VERSION ""

NS_ :

BS_:

BU_:

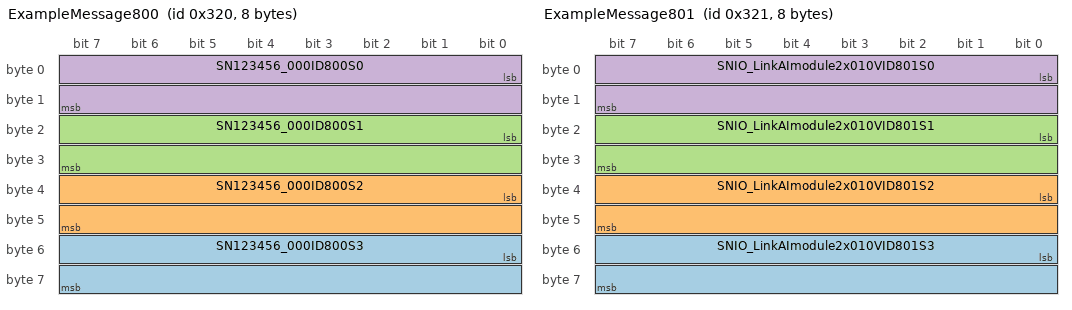
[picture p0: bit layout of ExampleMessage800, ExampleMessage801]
BO_ 800 ExampleMessage800: 8 Vector__XXX
 SG_ SN123456_000ID800S3 : 48|16@1+ (1,0) [-3000|3000] "unit" Vector__XXX
 SG_ SN123456_000ID800S2 : 32|16@1+ (1,0) [-3000|3000] "unit" Vector__XXX
 SG_ SN123456_000ID800S1 : 16|16@1+ (1,0) [-3000|3000] "unit" Vector__XXX
 SG_ SN123456_000ID800S0 : 0|16@1+ (1,0) [-3000|3000] "unit" Vector__XXX

BO_ 801 ExampleMessage801: 8 Vector__XXX
 SG_ SNIO_LinkAImodule2x010VID801S3 : 48|16@1+ (1,0) [-3000|3000] "unit" Vector__XXX
 SG_ SNIO_LinkAImodule2x010VID801S2 : 32|16@1+ (1,0) [-3000|3000] "unit" Vector__XXX
 SG_ SNIO_LinkAImodule2x010VID801S1 : 16|16@1+ (1,0) [-3000|3000] "unit" Vector__XXX
 SG_ SNIO_LinkAImodule2x010VID801S0 : 0|16@1+ (1,0) [-3000|3000] "unit" Vector__XXX

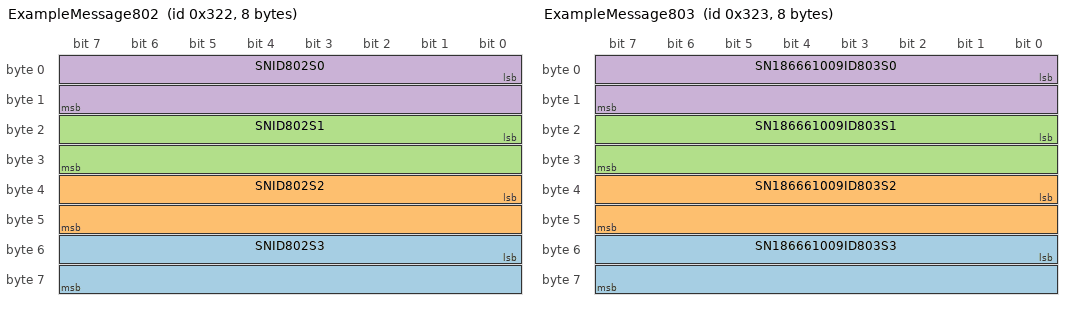
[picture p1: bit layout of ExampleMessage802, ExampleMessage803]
BO_ 802 ExampleMessage802: 8 Vector__XXX
 SG_ SNID802S3 : 48|16@1+ (1,0) [-3000|3000] "unit" Vector__XXX
 SG_ SNID802S2 : 32|16@1+ (1,0) [-3000|3000] "unit" Vector__XXX
 SG_ SNID802S1 : 16|16@1+ (1,0) [-3000|3000] "unit" Vector__XXX
 SG_ SNID802S0 : 0|16@1+ (1,0) [-3000|3000] "unit" Vector__XXX

BO_ 803 ExampleMessage803: 8 Vector__XXX
 SG_ SN186661009ID803S3 : 48|16@1+ (1,0) [-3000|3000] "unit" Vector__XXX
 SG_ SN186661009ID803S2 : 32|16@1+ (1,0) [-3000|3000] "unit" Vector__XXX
 SG_ SN186661009ID803S1 : 16|16@1+ (1,0) [-3000|3000] "unit" Vector__XXX
 SG_ SN186661009ID803S0 : 0|16@1+ (1,0) [-3000|3000] "unit" Vector__XXX

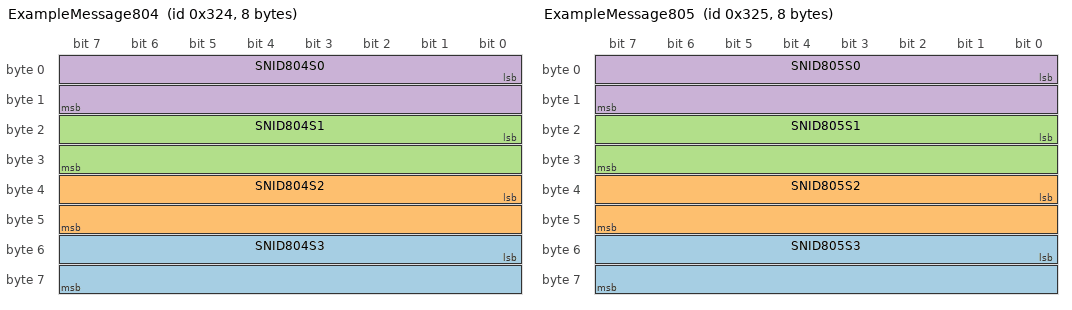
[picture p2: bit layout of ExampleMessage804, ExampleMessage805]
BO_ 804 ExampleMessage804: 8 Vector__XXX
 SG_ SNID804S3 : 48|16@1+ (1,0) [-3000|3000] "unit" Vector__XXX
 SG_ SNID804S2 : 32|16@1+ (1,0) [-3000|3000] "unit" Vector__XXX
 SG_ SNID804S1 : 16|16@1+ (1,0) [-3000|3000] "unit" Vector__XXX
 SG_ SNID804S0 : 0|16@1+ (1,0) [-3000|3000] "unit" Vector__XXX

BO_ 805 ExampleMessage805: 8 Vector__XXX
 SG_ SNID805S3 : 48|16@1+ (1,0) [-3000|3000] "unit" Vector__XXX
 SG_ SNID805S2 : 32|16@1+ (1,0) [-3000|3000] "unit" Vector__XXX
 SG_ SNID805S1 : 16|16@1+ (1,0) [-3000|3000] "unit" Vector__XXX
 SG_ SNID805S0 : 0|16@1+ (1,0) [-3000|3000] "unit" Vector__XXX

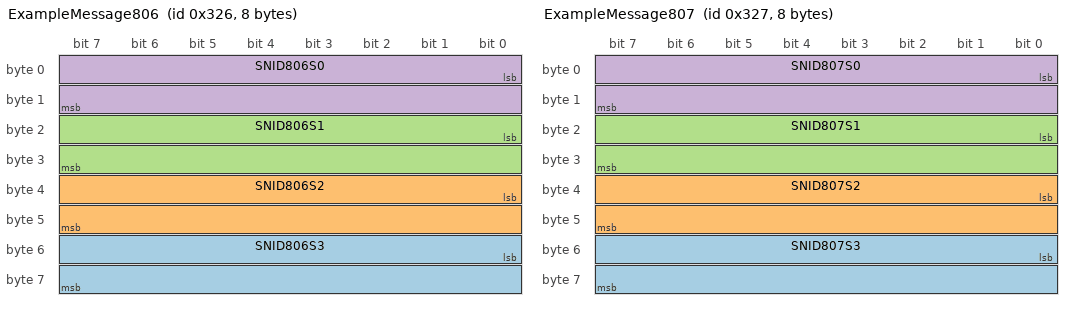
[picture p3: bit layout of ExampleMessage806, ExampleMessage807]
BO_ 806 ExampleMessage806: 8 Vector__XXX
 SG_ SNID806S3 : 48|16@1+ (1,0) [-3000|3000] "unit" Vector__XXX
 SG_ SNID806S2 : 32|16@1+ (1,0) [-3000|3000] "unit" Vector__XXX
 SG_ SNID806S1 : 16|16@1+ (1,0) [-3000|3000] "unit" Vector__XXX
 SG_ SNID806S0 : 0|16@1+ (1,0) [-3000|3000] "unit" Vector__XXX

BO_ 807 ExampleMessage807: 8 Vector__XXX
 SG_ SNID807S3 : 48|16@1+ (1,0) [-3000|3000] "unit" Vector__XXX
 SG_ SNID807S2 : 32|16@1+ (1,0) [-3000|3000] "unit" Vector__XXX
 SG_ SNID807S1 : 16|16@1+ (1,0) [-3000|3000] "unit" Vector__XXX
 SG_ SNID807S0 : 0|16@1+ (1,0) [-3000|3000] "unit" Vector__XXX

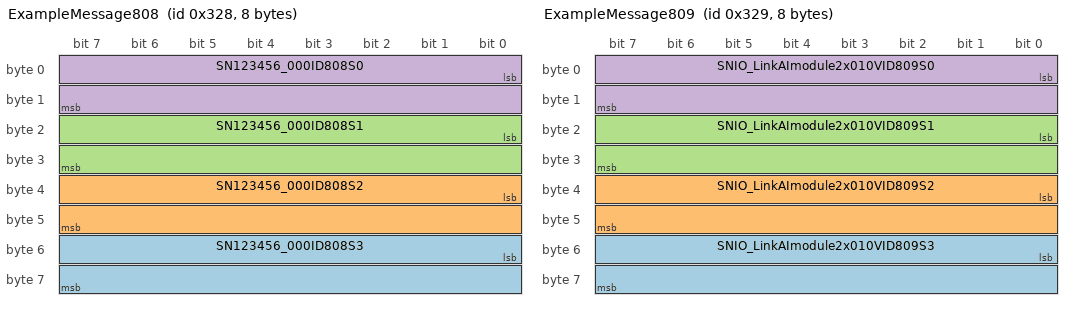
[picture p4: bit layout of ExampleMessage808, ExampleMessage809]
BO_ 808 ExampleMessage808: 8 Vector__XXX
 SG_ SN123456_000ID808S3 : 48|16@1+ (1,0) [-3000|3000] "unit" Vector__XXX
 SG_ SN123456_000ID808S2 : 32|16@1+ (1,0) [-3000|3000] "unit" Vector__XXX
 SG_ SN123456_000ID808S1 : 16|16@1+ (1,0) [-3000|3000] "unit" Vector__XXX
 SG_ SN123456_000ID808S0 : 0|16@1+ (1,0) [-3000|3000] "unit" Vector__XXX

BO_ 809 ExampleMessage809: 8 Vector__XXX
 SG_ SNIO_LinkAImodule2x010VID809S3 : 48|16@1+ (1,0) [-3000|3000] "unit" Vector__XXX
 SG_ SNIO_LinkAImodule2x010VID809S2 : 32|16@1+ (1,0) [-3000|3000] "unit" Vector__XXX
 SG_ SNIO_LinkAImodule2x010VID809S1 : 16|16@1+ (1,0) [-3000|3000] "unit" Vector__XXX
 SG_ SNIO_LinkAImodule2x010VID809S0 : 0|16@1+ (1,0) [-3000|3000] "unit" Vector__XXX

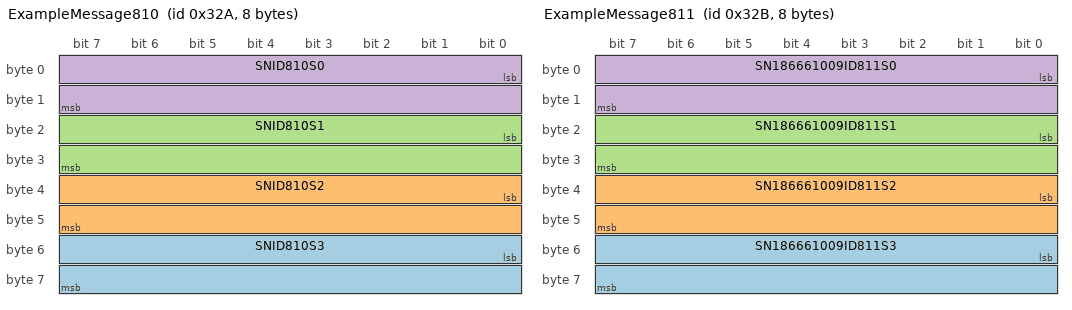
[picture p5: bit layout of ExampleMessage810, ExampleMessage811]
BO_ 810 ExampleMessage810: 8 Vector__XXX
 SG_ SNID810S3 : 48|16@1+ (1,0) [-3000|3000] "unit" Vector__XXX
 SG_ SNID810S2 : 32|16@1+ (1,0) [-3000|3000] "unit" Vector__XXX
 SG_ SNID810S1 : 16|16@1+ (1,0) [-3000|3000] "unit" Vector__XXX
 SG_ SNID810S0 : 0|16@1+ (1,0) [-3000|3000] "unit" Vector__XXX

BO_ 811 ExampleMessage811: 8 Vector__XXX
 SG_ SN186661009ID811S3 : 48|16@1+ (1,0) [-3000|3000] "unit" Vector__XXX
 SG_ SN186661009ID811S2 : 32|16@1+ (1,0) [-3000|3000] "unit" Vector__XXX
 SG_ SN186661009ID811S1 : 16|16@1+ (1,0) [-3000|3000] "unit" Vector__XXX
 SG_ SN186661009ID811S0 : 0|16@1+ (1,0) [-3000|3000] "unit" Vector__XXX

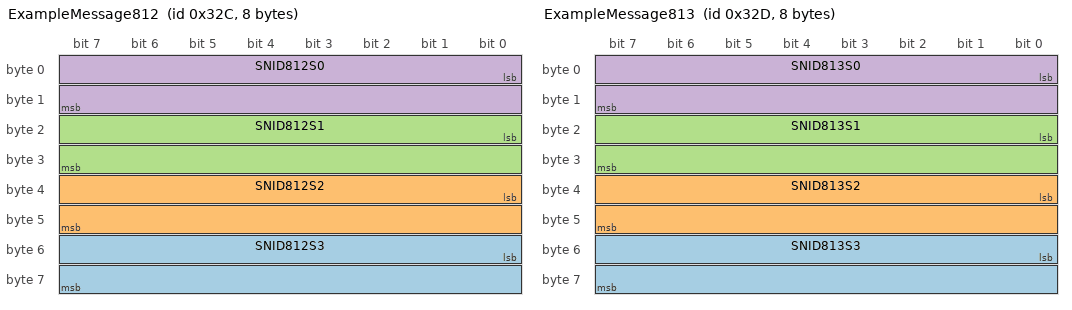
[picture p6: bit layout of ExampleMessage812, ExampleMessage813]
BO_ 812 ExampleMessage812: 8 Vector__XXX
 SG_ SNID812S3 : 48|16@1+ (1,0) [-3000|3000] "unit" Vector__XXX
 SG_ SNID812S2 : 32|16@1+ (1,0) [-3000|3000] "unit" Vector__XXX
 SG_ SNID812S1 : 16|16@1+ (1,0) [-3000|3000] "unit" Vector__XXX
 SG_ SNID812S0 : 0|16@1+ (1,0) [-3000|3000] "unit" Vector__XXX

BO_ 813 ExampleMessage813: 8 Vector__XXX
 SG_ SNID813S3 : 48|16@1+ (1,0) [-3000|3000] "unit" Vector__XXX
 SG_ SNID813S2 : 32|16@1+ (1,0) [-3000|3000] "unit" Vector__XXX
 SG_ SNID813S1 : 16|16@1+ (1,0) [-3000|3000] "unit" Vector__XXX
 SG_ SNID813S0 : 0|16@1+ (1,0) [-3000|3000] "unit" Vector__XXX

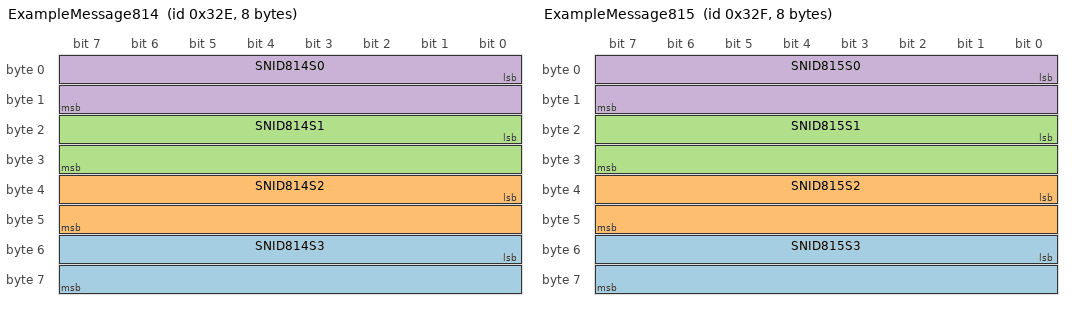
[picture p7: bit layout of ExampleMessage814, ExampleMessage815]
BO_ 814 ExampleMessage814: 8 Vector__XXX
 SG_ SNID814S3 : 48|16@1+ (1,0) [-3000|3000] "unit" Vector__XXX
 SG_ SNID814S2 : 32|16@1+ (1,0) [-3000|3000] "unit" Vector__XXX
 SG_ SNID814S1 : 16|16@1+ (1,0) [-3000|3000] "unit" Vector__XXX
 SG_ SNID814S0 : 0|16@1+ (1,0) [-3000|3000] "unit" Vector__XXX

BO_ 815 ExampleMessage815: 8 Vector__XXX
 SG_ SNID815S3 : 48|16@1+ (1,0) [-3000|3000] "unit" Vector__XXX
 SG_ SNID815S2 : 32|16@1+ (1,0) [-3000|3000] "unit" Vector__XXX
 SG_ SNID815S1 : 16|16@1+ (1,0) [-3000|3000] "unit" Vector__XXX
 SG_ SNID815S0 : 0|16@1+ (1,0) [-3000|3000] "unit" Vector__XXX

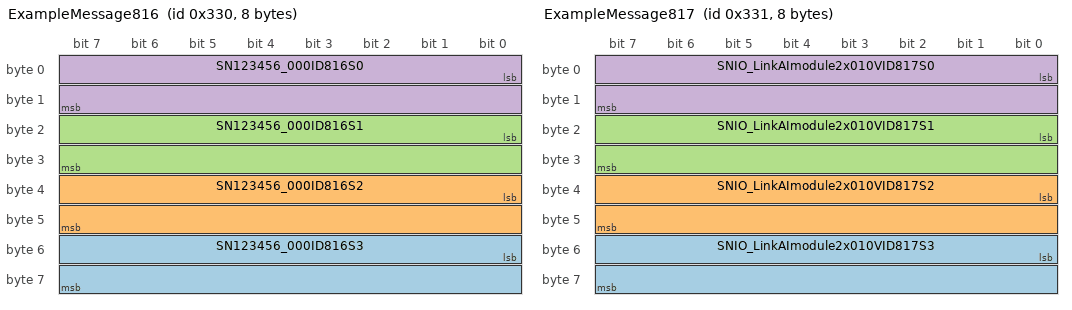
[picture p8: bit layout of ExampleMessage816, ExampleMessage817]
BO_ 816 ExampleMessage816: 8 Vector__XXX
 SG_ SN123456_000ID816S3 : 48|16@1+ (1,0) [-3000|3000] "unit" Vector__XXX
 SG_ SN123456_000ID816S2 : 32|16@1+ (1,0) [-3000|3000] "unit" Vector__XXX
 SG_ SN123456_000ID816S1 : 16|16@1+ (1,0) [-3000|3000] "unit" Vector__XXX
 SG_ SN123456_000ID816S0 : 0|16@1+ (1,0) [-3000|3000] "unit" Vector__XXX

BO_ 817 ExampleMessage817: 8 Vector__XXX
 SG_ SNIO_LinkAImodule2x010VID817S3 : 48|16@1+ (1,0) [-3000|3000] "unit" Vector__XXX
 SG_ SNIO_LinkAImodule2x010VID817S2 : 32|16@1+ (1,0) [-3000|3000] "unit" Vector__XXX
 SG_ SNIO_LinkAImodule2x010VID817S1 : 16|16@1+ (1,0) [-3000|3000] "unit" Vector__XXX
 SG_ SNIO_LinkAImodule2x010VID817S0 : 0|16@1+ (1,0) [-3000|3000] "unit" Vector__XXX

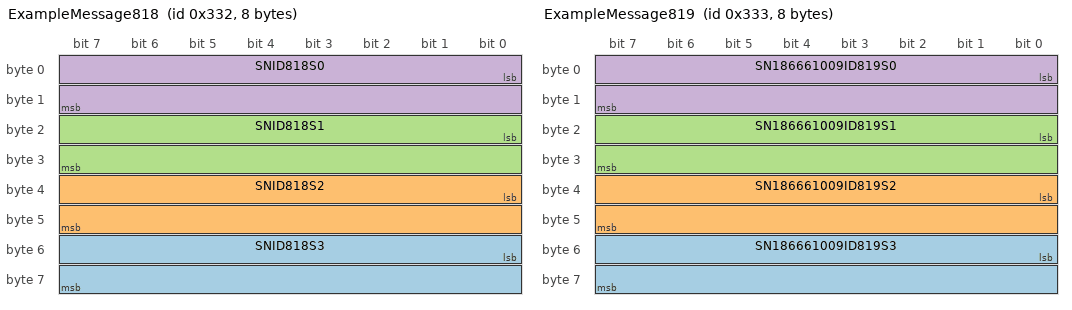
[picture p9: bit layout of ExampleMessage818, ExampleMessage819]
BO_ 818 ExampleMessage818: 8 Vector__XXX
 SG_ SNID818S3 : 48|16@1+ (1,0) [-3000|3000] "unit" Vector__XXX
 SG_ SNID818S2 : 32|16@1+ (1,0) [-3000|3000] "unit" Vector__XXX
 SG_ SNID818S1 : 16|16@1+ (1,0) [-3000|3000] "unit" Vector__XXX
 SG_ SNID818S0 : 0|16@1+ (1,0) [-3000|3000] "unit" Vector__XXX

BO_ 819 ExampleMessage819: 8 Vector__XXX
 SG_ SN186661009ID819S3 : 48|16@1+ (1,0) [-3000|3000] "unit" Vector__XXX
 SG_ SN186661009ID819S2 : 32|16@1+ (1,0) [-3000|3000] "unit" Vector__XXX
 SG_ SN186661009ID819S1 : 16|16@1+ (1,0) [-3000|3000] "unit" Vector__XXX
 SG_ SN186661009ID819S0 : 0|16@1+ (1,0) [-3000|3000] "unit" Vector__XXX

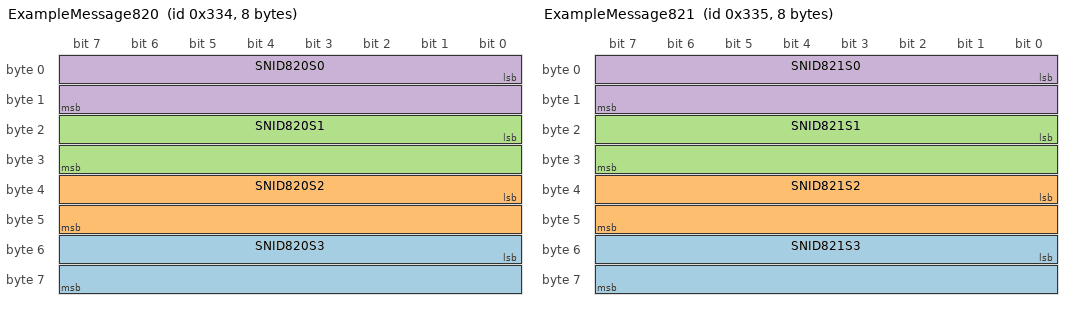
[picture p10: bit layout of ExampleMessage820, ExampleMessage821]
BO_ 820 ExampleMessage820: 8 Vector__XXX
 SG_ SNID820S3 : 48|16@1+ (1,0) [-3000|3000] "unit" Vector__XXX
 SG_ SNID820S2 : 32|16@1+ (1,0) [-3000|3000] "unit" Vector__XXX
 SG_ SNID820S1 : 16|16@1+ (1,0) [-3000|3000] "unit" Vector__XXX
 SG_ SNID820S0 : 0|16@1+ (1,0) [-3000|3000] "unit" Vector__XXX

BO_ 821 ExampleMessage821: 8 Vector__XXX
 SG_ SNID821S3 : 48|16@1+ (1,0) [-3000|3000] "unit" Vector__XXX
 SG_ SNID821S2 : 32|16@1+ (1,0) [-3000|3000] "unit" Vector__XXX
 SG_ SNID821S1 : 16|16@1+ (1,0) [-3000|3000] "unit" Vector__XXX
 SG_ SNID821S0 : 0|16@1+ (1,0) [-3000|3000] "unit" Vector__XXX

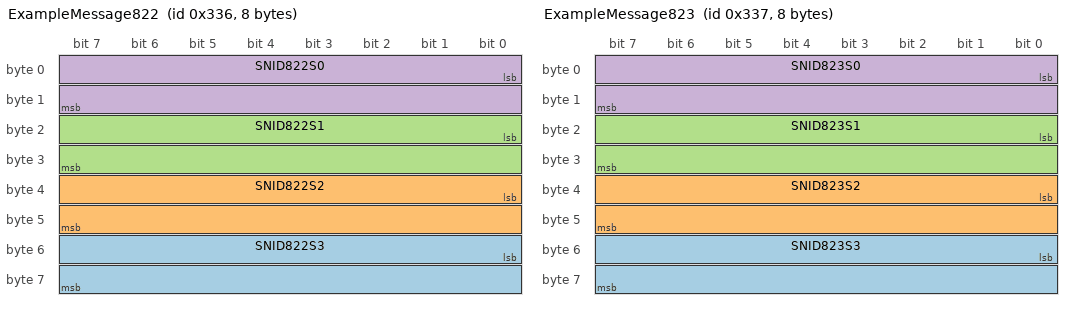
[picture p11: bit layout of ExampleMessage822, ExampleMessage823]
BO_ 822 ExampleMessage822: 8 Vector__XXX
 SG_ SNID822S3 : 48|16@1+ (1,0) [-3000|3000] "unit" Vector__XXX
 SG_ SNID822S2 : 32|16@1+ (1,0) [-3000|3000] "unit" Vector__XXX
 SG_ SNID822S1 : 16|16@1+ (1,0) [-3000|3000] "unit" Vector__XXX
 SG_ SNID822S0 : 0|16@1+ (1,0) [-3000|3000] "unit" Vector__XXX

BO_ 823 ExampleMessage823: 8 Vector__XXX
 SG_ SNID823S3 : 48|16@1+ (1,0) [-3000|3000] "unit" Vector__XXX
 SG_ SNID823S2 : 32|16@1+ (1,0) [-3000|3000] "unit" Vector__XXX
 SG_ SNID823S1 : 16|16@1+ (1,0) [-3000|3000] "unit" Vector__XXX
 SG_ SNID823S0 : 0|16@1+ (1,0) [-3000|3000] "unit" Vector__XXX

CM_ SG_ 800 SN123456_000ID800S3 "IOLink SN123456_000ID800S3 www.novotechnik.de 
 MC1-2200-000-A00-000 
 MC1-SSP-S 
 MagneticMultiturnSensor 
 123456_000 
";
CM_ SG_ 800 SN123456_000ID800S2 "IOLink SN123456_000ID800S2 www.novotechnik.de 
 MC1-2200-000-A00-000 
 MC1-SSP-S 
 MagneticMultiturnSensor 
 123456_000 
";
CM_ SG_ 800 SN123456_000ID800S1 "IOLink SN123456_000ID800S1 www.novotechnik.de 
 MC1-2200-000-A00-000 
 MC1-SSP-S 
 MagneticMultiturnSensor 
 123456_000 
";
CM_ SG_ 800 SN123456_000ID800S0 "IOLink SN123456_000ID800S0 www.novotechnik.de 
 MC1-2200-000-A00-000 
 MC1-SSP-S 
 MagneticMultiturnSensor 
 123456_000 
";
CM_ SG_ 801 SNIO_LinkAImodule2x010VID801S3 "IOLink SNIO_LinkAImodule2x010VID801S3 IO-LinkAImodule2x0..10V 
";
CM_ SG_ 801 SNIO_LinkAImodule2x010VID801S2 "IOLink SNIO_LinkAImodule2x010VID801S2 IO-LinkAImodule2x0..10V 
";
CM_ SG_ 801 SNIO_LinkAImodule2x010VID801S1 "IOLink SNIO_LinkAImodule2x010VID801S1 IO-LinkAImodule2x0..10V 
";
CM_ SG_ 801 SNIO_LinkAImodule2x010VID801S0 "IOLink SNIO_LinkAImodule2x010VID801S0 IO-LinkAImodule2x0..10V 
";
CM_ SG_ 802 SNID802S3 "IOLink SNID802S3";
CM_ SG_ 802 SNID802S2 "IOLink SNID802S2";
CM_ SG_ 802 SNID802S1 "IOLink SNID802S1";
CM_ SG_ 802 SNID802S0 "IOLink SNID802S0";
CM_ SG_ 803 SN186661009ID803S3 "IOLink SN186661009ID803S3 www.novotechnik.de 
 RFC-4852-214-A11-551 
 RFC-P-ST 
 MagneticRotarySensor 
 186661009 
";
CM_ SG_ 803 SN186661009ID803S2 "IOLink SN186661009ID803S2 www.novotechnik.de 
 RFC-4852-214-A11-551 
 RFC-P-ST 
 MagneticRotarySensor 
 186661009 
";
CM_ SG_ 803 SN186661009ID803S1 "IOLink SN186661009ID803S1 www.novotechnik.de 
 RFC-4852-214-A11-551 
 RFC-P-ST 
 MagneticRotarySensor 
 186661009 
";
CM_ SG_ 803 SN186661009ID803S0 "IOLink SN186661009ID803S0 www.novotechnik.de 
 RFC-4852-214-A11-551 
 RFC-P-ST 
 MagneticRotarySensor 
 186661009 
";
CM_ SG_ 804 SNID804S3 "IOLink SNID804S3";
CM_ SG_ 804 SNID804S2 "IOLink SNID804S2";
CM_ SG_ 804 SNID804S1 "IOLink SNID804S1";
CM_ SG_ 804 SNID804S0 "IOLink SNID804S0";
CM_ SG_ 805 SNID805S3 "IOLink SNID805S3";
CM_ SG_ 805 SNID805S2 "IOLink SNID805S2";
CM_ SG_ 805 SNID805S1 "IOLink SNID805S1";
CM_ SG_ 805 SNID805S0 "IOLink SNID805S0";
CM_ SG_ 806 SNID806S3 "IOLink SNID806S3";
CM_ SG_ 806 SNID806S2 "IOLink SNID806S2";
CM_ SG_ 806 SNID806S1 "IOLink SNID806S1";
CM_ SG_ 806 SNID806S0 "IOLink SNID806S0";
CM_ SG_ 807 SNID807S3 "IOLink SNID807S3";
CM_ SG_ 807 SNID807S2 "IOLink SNID807S2";
CM_ SG_ 807 SNID807S1 "IOLink SNID807S1";
CM_ SG_ 807 SNID807S0 "IOLink SNID807S0";
CM_ SG_ 808 SN123456_000ID808S3 "IOLink SN123456_000ID808S3 www.novotechnik.de 
 MC1-2200-000-A00-000 
 MC1-SSP-S 
 MagneticMultiturnSensor 
 123456_000 
";
CM_ SG_ 808 SN123456_000ID808S2 "IOLink SN123456_000ID808S2 www.novotechnik.de 
 MC1-2200-000-A00-000 
 MC1-SSP-S 
 MagneticMultiturnSensor 
 123456_000 
";
CM_ SG_ 808 SN123456_000ID808S1 "IOLink SN123456_000ID808S1 www.novotechnik.de 
 MC1-2200-000-A00-000 
 MC1-SSP-S 
 MagneticMultiturnSensor 
 123456_000 
";
CM_ SG_ 808 SN123456_000ID808S0 "IOLink SN123456_000ID808S0 www.novotechnik.de 
 MC1-2200-000-A00-000 
 MC1-SSP-S 
 MagneticMultiturnSensor 
 123456_000 
";
CM_ SG_ 809 SNIO_LinkAImodule2x010VID809S3 "IOLink SNIO_LinkAImodule2x010VID809S3 IO-LinkAImodule2x0..10V 
";
CM_ SG_ 809 SNIO_LinkAImodule2x010VID809S2 "IOLink SNIO_LinkAImodule2x010VID809S2 IO-LinkAImodule2x0..10V 
";
CM_ SG_ 809 SNIO_LinkAImodule2x010VID809S1 "IOLink SNIO_LinkAImodule2x010VID809S1 IO-LinkAImodule2x0..10V 
";
CM_ SG_ 809 SNIO_LinkAImodule2x010VID809S0 "IOLink SNIO_LinkAImodule2x010VID809S0 IO-LinkAImodule2x0..10V 
";
CM_ SG_ 810 SNID810S3 "IOLink SNID810S3";
CM_ SG_ 810 SNID810S2 "IOLink SNID810S2";
CM_ SG_ 810 SNID810S1 "IOLink SNID810S1";
CM_ SG_ 810 SNID810S0 "IOLink SNID810S0";
CM_ SG_ 811 SN186661009ID811S3 "IOLink SN186661009ID811S3 www.novotechnik.de 
 RFC-4852-214-A11-551 
 RFC-P-ST 
 MagneticRotarySensor 
 186661009 
";
CM_ SG_ 811 SN186661009ID811S2 "IOLink SN186661009ID811S2 www.novotechnik.de 
 RFC-4852-214-A11-551 
 RFC-P-ST 
 MagneticRotarySensor 
 186661009 
";
CM_ SG_ 811 SN186661009ID811S1 "IOLink SN186661009ID811S1 www.novotechnik.de 
 RFC-4852-214-A11-551 
 RFC-P-ST 
 MagneticRotarySensor 
 186661009 
";
CM_ SG_ 811 SN186661009ID811S0 "IOLink SN186661009ID811S0 www.novotechnik.de 
 RFC-4852-214-A11-551 
 RFC-P-ST 
 MagneticRotarySensor 
 186661009 
";
CM_ SG_ 812 SNID812S3 "IOLink SNID812S3";
CM_ SG_ 812 SNID812S2 "IOLink SNID812S2";
CM_ SG_ 812 SNID812S1 "IOLink SNID812S1";
CM_ SG_ 812 SNID812S0 "IOLink SNID812S0";
CM_ SG_ 813 SNID813S3 "IOLink SNID813S3";
CM_ SG_ 813 SNID813S2 "IOLink SNID813S2";
CM_ SG_ 813 SNID813S1 "IOLink SNID813S1";
CM_ SG_ 813 SNID813S0 "IOLink SNID813S0";
CM_ SG_ 814 SNID814S3 "IOLink SNID814S3";
CM_ SG_ 814 SNID814S2 "IOLink SNID814S2";
CM_ SG_ 814 SNID814S1 "IOLink SNID814S1";
CM_ SG_ 814 SNID814S0 "IOLink SNID814S0";
CM_ SG_ 815 SNID815S3 "IOLink SNID815S3";
CM_ SG_ 815 SNID815S2 "IOLink SNID815S2";
CM_ SG_ 815 SNID815S1 "IOLink SNID815S1";
CM_ SG_ 815 SNID815S0 "IOLink SNID815S0";
CM_ SG_ 816 SN123456_000ID816S3 "IOLink SN123456_000ID816S3 www.novotechnik.de 
 MC1-2200-000-A00-000 
 MC1-SSP-S 
 MagneticMultiturnSensor 
 123456_000 
";
CM_ SG_ 816 SN123456_000ID816S2 "IOLink SN123456_000ID816S2 www.novotechnik.de 
 MC1-2200-000-A00-000 
 MC1-SSP-S 
 MagneticMultiturnSensor 
 123456_000 
";
CM_ SG_ 816 SN123456_000ID816S1 "IOLink SN123456_000ID816S1 www.novotechnik.de 
 MC1-2200-000-A00-000 
 MC1-SSP-S 
 MagneticMultiturnSensor 
 123456_000 
";
CM_ SG_ 816 SN123456_000ID816S0 "IOLink SN123456_000ID816S0 www.novotechnik.de 
 MC1-2200-000-A00-000 
 MC1-SSP-S 
 MagneticMultiturnSensor 
 123456_000 
";
CM_ SG_ 817 SNIO_LinkAImodule2x010VID817S3 "IOLink SNIO_LinkAImodule2x010VID817S3 IO-LinkAImodule2x0..10V 
";
CM_ SG_ 817 SNIO_LinkAImodule2x010VID817S2 "IOLink SNIO_LinkAImodule2x010VID817S2 IO-LinkAImodule2x0..10V 
";
CM_ SG_ 817 SNIO_LinkAImodule2x010VID817S1 "IOLink SNIO_LinkAImodule2x010VID817S1 IO-LinkAImodule2x0..10V 
";
CM_ SG_ 817 SNIO_LinkAImodule2x010VID817S0 "IOLink SNIO_LinkAImodule2x010VID817S0 IO-LinkAImodule2x0..10V 
";
CM_ SG_ 818 SNID818S3 "IOLink SNID818S3";
CM_ SG_ 818 SNID818S2 "IOLink SNID818S2";
CM_ SG_ 818 SNID818S1 "IOLink SNID818S1";
CM_ SG_ 818 SNID818S0 "IOLink SNID818S0";
CM_ SG_ 819 SN186661009ID819S3 "IOLink SN186661009ID819S3 www.novotechnik.de 
 RFC-4852-214-A11-551 
 RFC-P-ST 
 MagneticRotarySensor 
 186661009 
";
CM_ SG_ 819 SN186661009ID819S2 "IOLink SN186661009ID819S2 www.novotechnik.de 
 RFC-4852-214-A11-551 
 RFC-P-ST 
 MagneticRotarySensor 
 186661009 
";
CM_ SG_ 819 SN186661009ID819S1 "IOLink SN186661009ID819S1 www.novotechnik.de 
 RFC-4852-214-A11-551 
 RFC-P-ST 
 MagneticRotarySensor 
 186661009 
";
CM_ SG_ 819 SN186661009ID819S0 "IOLink SN186661009ID819S0 www.novotechnik.de 
 RFC-4852-214-A11-551 
 RFC-P-ST 
 MagneticRotarySensor 
 186661009 
";
CM_ SG_ 820 SNID820S3 "IOLink SNID820S3";
CM_ SG_ 820 SNID820S2 "IOLink SNID820S2";
CM_ SG_ 820 SNID820S1 "IOLink SNID820S1";
CM_ SG_ 820 SNID820S0 "IOLink SNID820S0";
CM_ SG_ 821 SNID821S3 "IOLink SNID821S3";
CM_ SG_ 821 SNID821S2 "IOLink SNID821S2";
CM_ SG_ 821 SNID821S1 "IOLink SNID821S1";
CM_ SG_ 821 SNID821S0 "IOLink SNID821S0";
CM_ SG_ 822 SNID822S3 "IOLink SNID822S3";
CM_ SG_ 822 SNID822S2 "IOLink SNID822S2";
CM_ SG_ 822 SNID822S1 "IOLink SNID822S1";
CM_ SG_ 822 SNID822S0 "IOLink SNID822S0";
CM_ SG_ 823 SNID823S3 "IOLink SNID823S3";
CM_ SG_ 823 SNID823S2 "IOLink SNID823S2";
CM_ SG_ 823 SNID823S1 "IOLink SNID823S1";
CM_ SG_ 823 SNID823S0 "IOLink SNID823S0";
